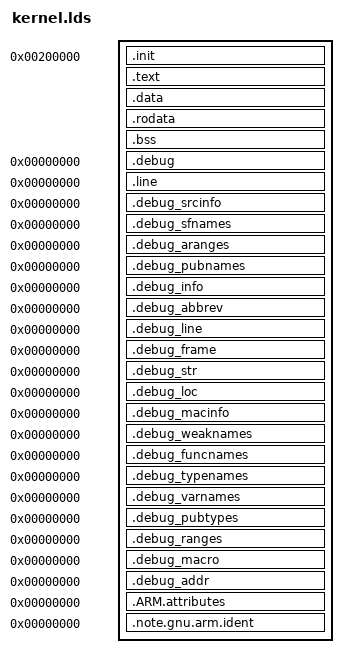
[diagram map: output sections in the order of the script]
ENTRY(_start)
SECTIONS
{
	. = 0x200000;
	.init : { *(.init) }
	.text : { *(.text) }
	
	/* ahh, yes. The empty & unused section ld is in love with */
	.data : { *(.data) }
	
	/* and once more with feeling */
	.rodata : { *(.rodata*) }

	.bss : { *(.bss)}

	/* debug stuffs, copied from ld -verbose */
	/* DWARF debug sections.
		Symbols in the DWARF debugging sections are relative to the beginning
		of the section so we begin them at 0.  */
	/* DWARF 1 */
	.debug          0 : { *(.debug) }
	.line           0 : { *(.line) }
	/* GNU DWARF 1 extensions */
	.debug_srcinfo  0 : { *(.debug_srcinfo) }
	.debug_sfnames  0 : { *(.debug_sfnames) }
	/* DWARF 1.1 and DWARF 2 */
	.debug_aranges  0 : { *(.debug_aranges) }
	.debug_pubnames 0 : { *(.debug_pubnames) }
	/* DWARF 2 */
	.debug_info     0 : { *(.debug_info .gnu.linkonce.wi.*) }
	.debug_abbrev   0 : { *(.debug_abbrev) }
	.debug_line     0 : { *(.debug_line .debug_line.* .debug_line_end) }
	.debug_frame    0 : { *(.debug_frame) }
	.debug_str      0 : { *(.debug_str) }
	.debug_loc      0 : { *(.debug_loc) }
	.debug_macinfo  0 : { *(.debug_macinfo) }
	/* SGI/MIPS DWARF 2 extensions */
	.debug_weaknames 0 : { *(.debug_weaknames) }
	.debug_funcnames 0 : { *(.debug_funcnames) }
	.debug_typenames 0 : { *(.debug_typenames) }
	.debug_varnames  0 : { *(.debug_varnames) }
	/* DWARF 3 */
	.debug_pubtypes 0 : { *(.debug_pubtypes) }
	.debug_ranges   0 : { *(.debug_ranges) }
	/* DWARF Extension.  */
	.debug_macro    0 : { *(.debug_macro) }
	.debug_addr     0 : { *(.debug_addr) }
	.ARM.attributes 0 : { KEEP (*(.ARM.attributes)) KEEP (*(.gnu.attributes)) }
	.note.gnu.arm.ident 0 : { KEEP (*(.note.gnu.arm.ident)) }

	/* FUCK OFF LD, We don't want your bullshit */
	/DISCARD/ : {*(*)}
}
